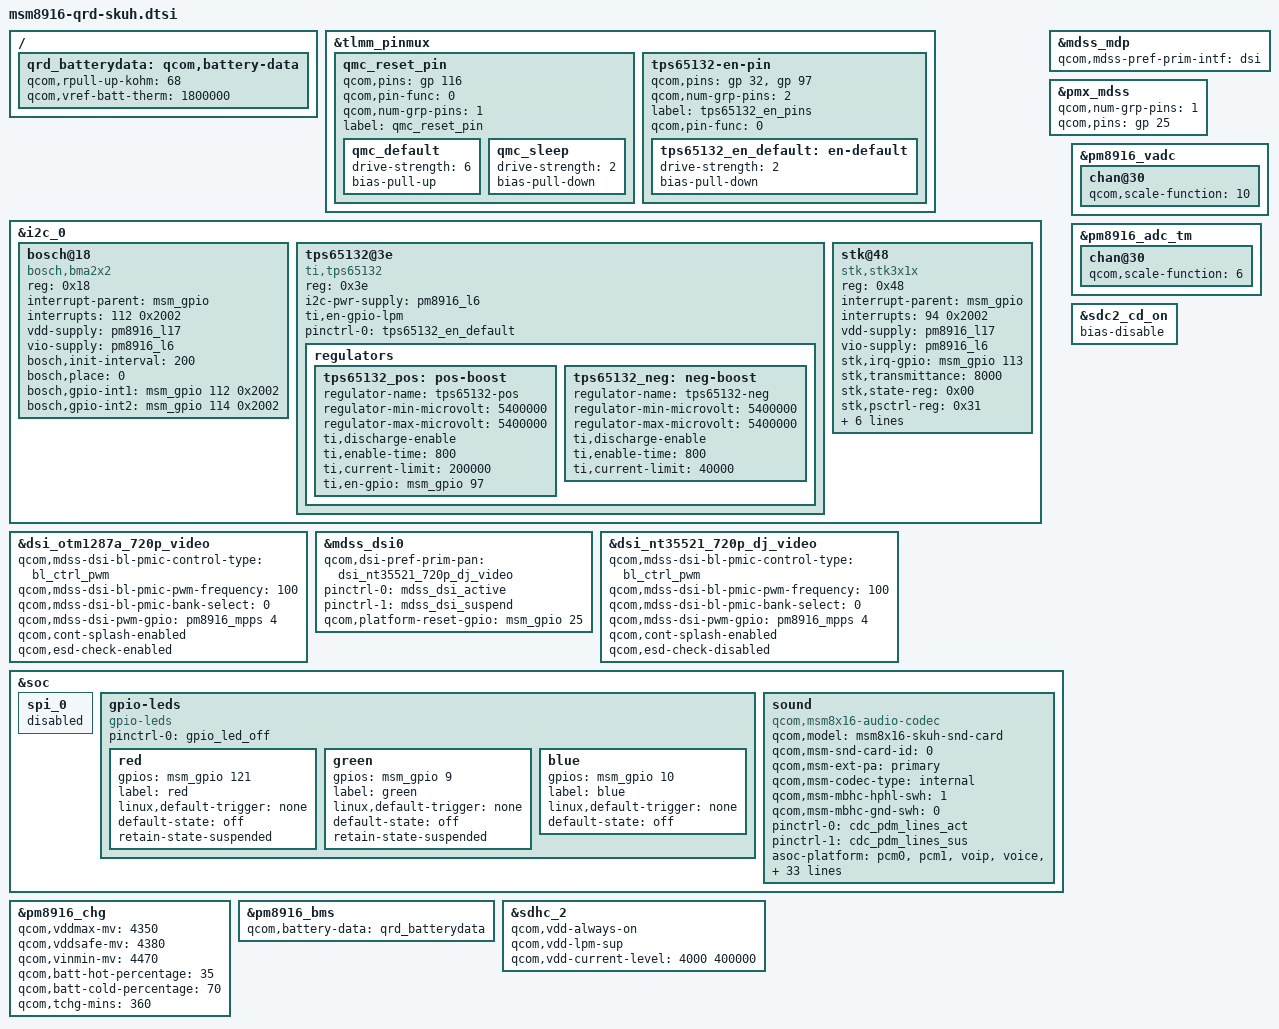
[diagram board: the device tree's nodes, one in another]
/* Copyright (c) 2015, The Linux Foundation. All rights reserved.
 *
 * This program is free software; you can redistribute it and/or modify
 * it under the terms of the GNU General Public License version 2 and
 * only version 2 as published by the Free Software Foundation.
 *
 * This program is distributed in the hope that it will be useful,
 * but WITHOUT ANY WARRANTY; without even the implied warranty of
 * MERCHANTABILITY or FITNESS FOR A PARTICULAR PURPOSE.  See the
 * GNU General Public License for more details.
 */

#include "msm8916-qrd.dtsi"
#include "dsi-panel-innolux-720p-video.dtsi"
#include "dsi-panel-otm1287a-720p-video.dtsi"
#include "dsi-panel-nt35521-720p-dj-video.dtsi"
#include "msm8916-camera-sensor-qrd.dtsi"

&tlmm_pinmux {
	qmc_reset_pin {
		qcom,pins = <&gp 116>;
		qcom,pin-func = <0>;
		qcom,num-grp-pins = <1>;
		label = "qmc_reset_pin";
		qmc_default: qmc_default {
			drive-strength = <6>;
			bias-pull-up;
		};
		qmc_sleep: qmc_sleep {
			drive-strength = <2>;
			bias-pull-down;
		};
	};

	tps65132-en-pin {
		qcom,pins = <&gp 32>, <&gp 97>;
		qcom,num-grp-pins = <2>;
		label = "tps65132_en_pins";
		qcom,pin-func = <0>;

		tps65132_en_default: en-default {
			drive-strength = <2>;
			bias-pull-down;
		};
	};
};

&i2c_0 { /* BLSP1 QUP2 */
	bosch@18 { /* Accelerometer sensor */ 
		compatible = "bosch,bma2x2";
		reg = <0x18>;
		pinctrl-names = "default";
		interrupt-parent = <&msm_gpio>;
		interrupts = <112 0x2002>;
		vdd-supply = <&pm8916_l17>;
		vio-supply = <&pm8916_l6>;
		bosch,init-interval = <200>;
		bosch,place = <0>;
		bosch,gpio-int1 = <&msm_gpio 112 0x2002>;
		bosch,gpio-int2 = <&msm_gpio 114 0x2002>; 
	};

	tps65132@3e {
		compatible = "ti,tps65132";
		reg = <0x3e>;
		i2c-pwr-supply = <&pm8916_l6>;
		ti,en-gpio-lpm;
		pinctrl-names = "default";
		pinctrl-0 = <&tps65132_en_default>;

		regulators {
			tps65132_pos: pos-boost {
				regulator-name = "tps65132-pos";
				regulator-min-microvolt = <5400000>;
				regulator-max-microvolt = <5400000>;
				ti,discharge-enable;
				ti,enable-time = <800>;
				ti,current-limit = <200000>;
				ti,en-gpio = <&msm_gpio 97 0>;
			};

			tps65132_neg: neg-boost {
				regulator-name = "tps65132-neg";
				regulator-min-microvolt = <5400000>;
				regulator-max-microvolt = <5400000>;
				ti,discharge-enable;
				ti,enable-time = <800>;
				ti,current-limit = <40000>;
			};
		};
	};

		stk@48 {
			compatible = "stk,stk3x1x";
			reg = <0x48>;
			interrupt-parent = <&msm_gpio>;
			interrupts = <94 0x2002>;
			vdd-supply = <&pm8916_l17>;
			vio-supply = <&pm8916_l6>;
			stk,irq-gpio = <&msm_gpio 113 0x2002>;
			stk,transmittance = <8000>;
			stk,state-reg = <0x00>;
			stk,psctrl-reg = <0x31>;
			stk,alsctrl-reg = <0x39>;
			stk,ledctrl-reg = <0xBF>;
			stk,wait-reg = <0x09>;
			stk,ps-thdh = <100>;
			stk,ps-thdl = <50>;
			stk,use-fir;
		};
};

&mdss_mdp {
	qcom,mdss-pref-prim-intf = "dsi";
};

&pmx_mdss {
	qcom,num-grp-pins = <1>;
	qcom,pins = <&gp 25>;
};

&dsi_otm1287a_720p_video {
	qcom,mdss-dsi-bl-pmic-control-type = "bl_ctrl_pwm";
	qcom,mdss-dsi-bl-pmic-pwm-frequency = <100>;
	qcom,mdss-dsi-bl-pmic-bank-select = <0>;
	qcom,mdss-dsi-pwm-gpio = <&pm8916_mpps 4 0>;
};

&mdss_dsi0 {
	qcom,dsi-pref-prim-pan = <&dsi_otm1287a_720p_video>;
	pinctrl-names = "mdss_default", "mdss_sleep";
	pinctrl-0 = <&mdss_dsi_active>;
	pinctrl-1 = <&mdss_dsi_suspend>;
	qcom,platform-reset-gpio = <&msm_gpio 25 0>;
};
&dsi_otm1287a_720p_video {
	qcom,cont-splash-enabled;
	qcom,esd-check-enabled;
};

&dsi_nt35521_720p_dj_video {
	qcom,mdss-dsi-bl-pmic-control-type = "bl_ctrl_pwm";
	qcom,mdss-dsi-bl-pmic-pwm-frequency = <100>;
	qcom,mdss-dsi-bl-pmic-bank-select = <0>;
	qcom,mdss-dsi-pwm-gpio = <&pm8916_mpps 4 0>;
};

&mdss_dsi0 {
	qcom,dsi-pref-prim-pan = <&dsi_nt35521_720p_dj_video>;
	pinctrl-names = "mdss_default", "mdss_sleep";
	pinctrl-0 = <&mdss_dsi_active>;
	pinctrl-1 = <&mdss_dsi_suspend>;
	qcom,platform-reset-gpio = <&msm_gpio 25 0>;
};
&dsi_nt35521_720p_dj_video {
	qcom,cont-splash-enabled;
	qcom,esd-check-disabled;
};

&soc {
	spi_0 {
		status = "disabled";
	};

	gpio-leds {
		compatible = "gpio-leds";
		status = "okay";
		pinctrl-names = "default";
		pinctrl-0 = <&gpio_led_off>;

		red {
			gpios = <&msm_gpio 121 0>;
			label = "red";
			linux,default-trigger = "none";
			default-state = "off";
			retain-state-suspended;
		};

		green {
			gpios = <&msm_gpio 9 0>;
			label = "green";
			linux,default-trigger = "none";
			default-state = "off";
			retain-state-suspended;
		};

		blue {
			gpios = <&msm_gpio 10 0>;
			label = "blue";
			linux,default-trigger = "none";
			default-state = "off";
		};
	};

	sound {
			compatible = "qcom,msm8x16-audio-codec";
			qcom,model = "msm8x16-skuh-snd-card";
			qcom,msm-snd-card-id = <0>;
			qcom,msm-ext-pa = "primary";
			qcom,msm-codec-type = "internal";
			qcom,msm-mbhc-hphl-swh = <1>;
			qcom,msm-mbhc-gnd-swh = <0>;
			pinctrl-names = "cdc_lines_act",
					"cdc_lines_sus";
			pinctrl-0 = <&cdc_pdm_lines_act>;
			pinctrl-1 = <&cdc_pdm_lines_sus>;
			asoc-platform = <&pcm0>, <&pcm1>, <&voip>, <&voice>,
					<&loopback>, <&compress>, <&hostless>,
					<&afe>, <&lsm>, <&routing>, <&lpa>;
			asoc-platform-names = "msm-pcm-dsp.0", "msm-pcm-dsp.1",
					"msm-voip-dsp", "msm-pcm-voice", "msm-pcm-loopback",
					"msm-compress-dsp", "msm-pcm-hostless", "msm-pcm-afe",
					"msm-lsm-client", "msm-pcm-routing", "msm-pcm-lpa";
			asoc-cpu = <&dai_pri_auxpcm>, <&dai_hdmi>,
					<&dai_mi2s0>, <&dai_mi2s1>, <&dai_mi2s2>, <&dai_mi2s3>,
					<&sb_0_rx>, <&sb_0_tx>, <&sb_1_rx>, <&sb_1_tx>,
					<&sb_3_rx>, <&sb_3_tx>, <&sb_4_rx>, <&sb_4_tx>,
					<&bt_sco_rx>, <&bt_sco_tx>, <&bt_a2dp_rx>,
					<&int_fm_rx>, <&int_fm_tx>,
					<&afe_pcm_rx>, <&afe_pcm_tx>, <&afe_proxy_rx>,
					<&afe_proxy_tx>, <&incall_record_rx>,
					<&incall_record_tx>, <&incall_music_rx>,
					<&incall_music_2_rx>;
			asoc-cpu-names = "msm-dai-q6-auxpcm.1", "msm-dai-q6-hdmi.8",
					"msm-dai-q6-mi2s.0", "msm-dai-q6-mi2s.1",
					"msm-dai-q6-mi2s.2", "msm-dai-q6-mi2s.3",
					"msm-dai-q6-dev.16384", "msm-dai-q6-dev.16385",
					"msm-dai-q6-dev.16386", "msm-dai-q6-dev.16387",
					"msm-dai-q6-dev.16390", "msm-dai-q6-dev.16391",
					"msm-dai-q6-dev.16392", "msm-dai-q6-dev.16393",
					"msm-dai-q6-dev.12288", "msm-dai-q6-dev.12289",
					"msm-dai-q6-dev.12290", "msm-dai-q6-dev.12292",
					"msm-dai-q6-dev.12293",	"msm-dai-q6-dev.224",
					"msm-dai-q6-dev.225", "msm-dai-q6-dev.241",
					"msm-dai-q6-dev.240", "msm-dai-q6-dev.32771",
					"msm-dai-q6-dev.32772", "msm-dai-q6-dev.32773",
					"msm-dai-q6-dev.32770";
			asoc-codec = <&stub_codec>, <&pm8916_tombak_dig>;
			asoc-codec-names = "msm-stub-codec.1", "tombak_codec";
	};
};

&pm8916_vadc {
	chan@30 {
		qcom,scale-function = <10>;
	};
};

&pm8916_adc_tm {
	chan@30 {
		qcom,scale-function = <6>;
	};
};

&pm8916_chg {
	qcom,vddmax-mv = <4350>;
	qcom,vddsafe-mv = <4380>;
	qcom,vinmin-mv = <4470>;
	qcom,batt-hot-percentage = <35>;
	qcom,batt-cold-percentage = <70>;
	qcom,tchg-mins = <360>;
	status = "okay";
};

/ {
	qrd_batterydata: qcom,battery-data {
		qcom,rpull-up-kohm = <68>;
		qcom,vref-batt-therm = <1800000>;

		#include "batterydata-uni-L500C-4v35-2100mah.dtsi"
	};
};

&pm8916_bms {
	status = "ok";
	qcom,battery-data = <&qrd_batterydata>;
};

&sdc2_cd_on {
	/delete-property/ bias-pull-up;
	bias-disable;
};

&sdhc_2 {
	qcom,vdd-always-on;
	qcom,vdd-lpm-sup;

	qcom,vdd-current-level = <4000 400000>;
};
